# SAMA7D65D1GN2 register map
Vendor: Microchip Technology; Series: SAMA7D6; File version: 0
Registers are 32-bit, read-write, reset 0x0 unless marked. A register's access mark holds for its fields unless they carry their own. Offsets are from the block's base; [hi:lo] are bit positions; {n}, {i} and the like mark numbered series.

## LVDSC — LVDS Controller
Base 0xE1408000
0x00 CR wo — Control Register
  [0] SER_EN — LVDS Serializer Enable
    0=Disables the serializer of the LVDS; 1=Enables the serializer of the LVDS
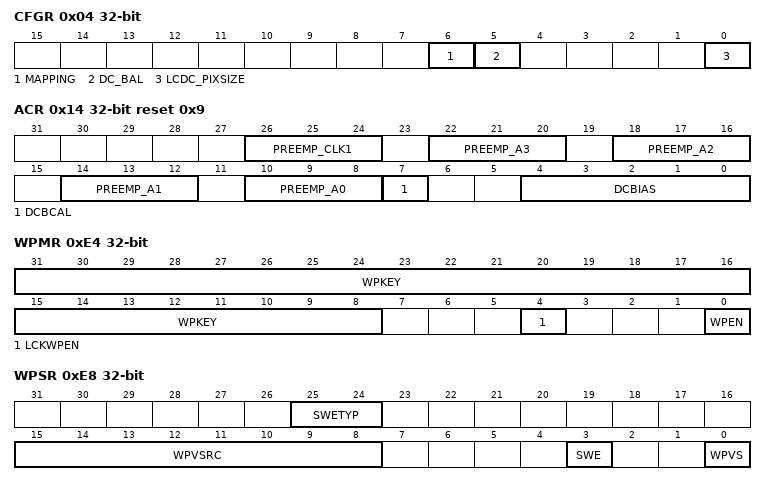
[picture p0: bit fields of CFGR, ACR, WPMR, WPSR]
0x04 CFGR — Configuration Register
  [6] MAPPING — LVDS mapping format (unbalanced mode only)
    0=VESA (Maps LVDS lanes to VESA format.); 1=JEIDA (Maps LVDS lanes to JEIDA format.)
  [5] DC_BAL — DC Mode
    0=UNBALANCED (LVDS lane is DC-unbalanced.); 1=BALANCED (LVDS lane is DC-balanced.)
  [0] LCDC_PIXSIZE — LCD Controller Pixel Size
    0=24BITS (LCD controller provides 24 bits per pixel.); 1=18BITS (LCD controller provides 18 bits per pixel.)
0x08 UCBR — User Control Bits Register
  [2] RESA3 — Lane A3 Reserved Bit Value
    0=Asserts a logical 0 on lane A3 reserved bit location; 1=Asserts a logical 1 on lane A3 reserved bit location
0x0C SR ro — Status Register
  [0] CS — Configuration Status
    0=The LVDSC_CFGRand LVDSC_UCBR registers can be modified; 1=The LVDSC_CFGRand LVDSC_UCBRregistersmust not be modified
0x14 ACR reset 0x9 — Analog Control Register
  [26:24] PREEMP_CLK1 — Pre-Emphasis Control for CLK LVDS Lane
  [4n+10:4n+8] PREEMP_A{n} (n=0..3) — Pre-Emphasis Control for Ax LVDS Lane
  [7] DCBCAL — DC Bias Calibration
    0=Configure DC bias with the DCBIAS field; 1=Configure DC bias with factory calibration value
  [4:0] DCBIAS — Common DC Bias Control for LVDS Lanes
0xE4 WPMR — Write Protection Mode Register
  [31:8] WPKEY — Write Protection Key
    0x4C5644=PASSWD (Writing any other value in this field aborts the write operation of the WPEN bit. Always reads as 0.)
  [4] LCKWPEN — Lock Write Protection Enable Until Next System Reset
    0=No effect; 1=Locks the WPEN bit to 1 until the next system reset if on the same access WPEN=1 and WPKEY corresponds to 0x4C5644 ('LVD' in ASCII)
  [0] WPEN — Write Protection Enable
    0=Disables write protection if WPKEY corresponds to 0x4C5644 ('LVD' in ASCII); 1=Enables write protection if WPKEY corresponds to 0x4C5644 ('LVD' in ASCII)
0xE8 WPSR ro — Write Protection Status Register
  [25:24] SWETYP — Software Error Type (cleared on read)
    1=WRITE_RO (LVDSC is enabled and a write access has been performed on a read-only register.); 2=UNDEF_RW (Access to an undefined address.); 3=WEIRD_ACTION (Tentative to modify the LVDSC_CFGR when LVDSC_CR.SER_EN=1.)
  [15:8] WPVSRC — Write Protection Violation Source
  [3] SWE — Software Control Error (cleared on read)
    0=No software error has occurred since the last read of LVDSC_WPSR; 1=A software error has occurred since the last read of LVDSC_WPSR. The field SWETYP details the type of software error; the associated incorrect software access is reported in the field WPVSRC (if WPVS=0).
  [0] WPVS — Write Protection Violation Status (cleared on read)
    0=No write protect violation has occurred since the last read of LVDSC_WPSR; 1=A write protect violation has occurred since the last read of LVDSC_WPSR. The address offset of the violated register is reported into field WPVSRC.

## RSTC — Reset Controller
Base 0xE001D100
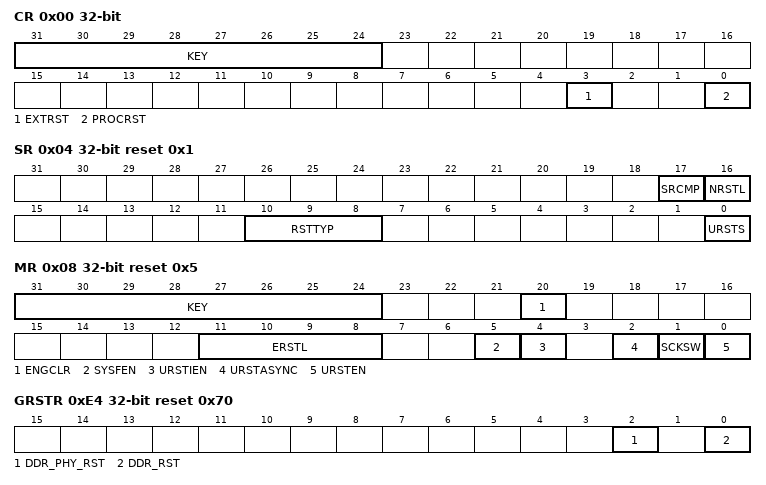
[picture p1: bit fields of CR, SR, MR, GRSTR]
0x00 CR wo — Control Register
  [31:24] KEY — System Reset Key
    165=PASSWD (Writing any other value in this field aborts the write operation.)
  [3] EXTRST — External Reset
    0=No effect; 1=If KEY = 0xA5, asserts the NRST_OUT pin
  [0] PROCRST — Processor Reset
    0=No effect; 1=If KEY = 0xA5, resets the processor and all the embedded peripherals
0x04 SR ro reset 0x1 — Status Register
  [17] SRCMP — Software Reset Command in Progress
    0=No software command is being performed by the RSTC. The RSTC is ready for a software command.; 1=A Software reset command is being performed by the RSTC. The RSTC is busy.
  [16] NRSTL — NRST Pin Level
  [10:8] RSTTYP — Reset Type
    0=GENERAL_RST (First powerup reset); 1=BACKUP_RST (Return from Backup mode); 2=WDT_RST (Watchdog fault occurred); 3=SOFT_RST (Processor reset required by the software); 4=USER_RST (NRST pin detected low); 6=MCK0_FAIL_RST (MCK0 failure detection occurred); 7=SLCK_XTAL_RST (32.768 kHz crystal failure detection fault occurred)
  [0] URSTS — User Reset Status
    0=No high-to-low edge on NRST happened since the last read of RSTC_SR; 1=At least one high-to-low transition of NRST has been detected since the last read of RSTC_SR
0x08 MR reset 0x5 — Mode Register
  [31:24] KEY — Write Access Password
    165=PASSWD (Writing any other value in this field aborts the write operation. Always reads as 0.)
  [20] ENGCLR — Enable GPBR Clear on Tamper Event
    0=Disables the GPBR immediate clear on tamper detection event; 1=Enables the GPBR immediate clear on tamper detection event
  [11:8] ERSTL — External Reset Length
  [5] SYSFEN — Main System Bus Clock (MCK0) Fail Enable
    0=The detection of a Main System Bus Clock (MCK0) failure has no effect; 1=The detection of a Main System Bus Clock (MCK0) failure resets the logic supplied by VDDCORE
  [4] URSTIEN — User Reset Interrupt Enable
    0=RSTC_SR.USRTS at '1' has no effect on the RSTC interrupt line; 1=RSTC_SR.USRTS at '1' asserts the RSTC interrupt line if URSTEN = 0
  [2] URSTASYNC — User Reset Asynchronous Control
    0=The NRST input signal is managed synchronously; 1=The NRST input signal is managed asynchronously. Note: this mode cannot be selected if the external bus interface drives an SDR/DDR memory device and another memory on the same bus.
  [1] SCKSW — Slow Clock Switching
    0=The detection of a 32.768 kHz crystal failure has no effect; 1=The detection of a 32.768 kHz crystal failure resets the logic supplied by VDDCORE
  [0] URSTEN — User Reset Enable
    0=The detection of a low level on the NRST pin does not generate a User reset; 1=The detection of a low level on the NRST pin triggers a User reset
0xE4 GRSTR reset 0x70 — Generic Reset Register
  [2] DDR_PHY_RST — DDR PHY Reset
    0=DDR PHY reset is asserted; 1=DDR PHY reset is de-asserted
  [0] DDR_RST — DDR Reset
    0=DDR Controller reset is asserted; 1=DDR Controller reset is de-asserted
